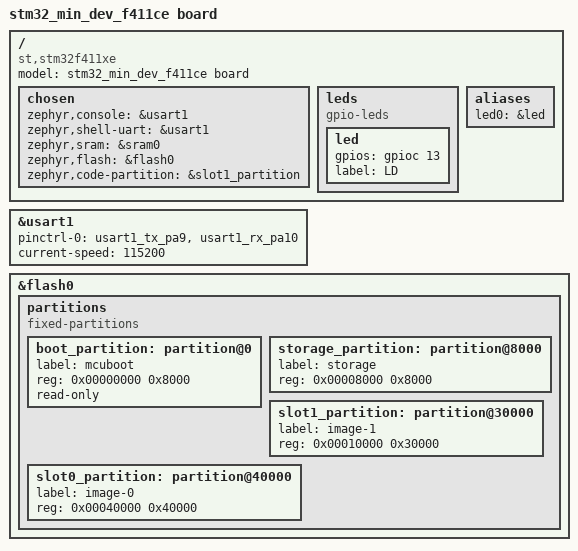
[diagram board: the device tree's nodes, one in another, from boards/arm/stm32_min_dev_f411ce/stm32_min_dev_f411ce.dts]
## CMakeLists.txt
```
# SPDX-License-Identifier: Apache-2.0

cmake_minimum_required(VERSION 3.13.1)

if( WIN32 ) # true if windows (32 and 64 bit)
set(GNUARMEMB_TOOLCHAIN_PATH "$ENV{GCC_ARM_HOME}")
endif()

set(ZEPHYR_TOOLCHAIN_VARIANT gnuarmemb)

list(APPEND BOARD_ROOT ${CMAKE_CURRENT_SOURCE_DIR})

message("----------------------------------------------------------------")
message("${BOARD_ROOT}")
message("${GNUARMEMB_TOOLCHAIN_PATH}")

find_package(Zephyr REQUIRED HINTS $ENV{ZEPHYR_BASE})


project(blinky)

target_sources(app PRIVATE src/main.c)
```

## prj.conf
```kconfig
CONFIG_GPIO=y
CONFIG_SIZE_OPTIMIZATIONS=y
```

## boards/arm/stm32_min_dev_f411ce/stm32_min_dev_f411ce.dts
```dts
/*
 * Copyright (c) 2017 Linaro Limited
 * Copyright (c) 2019 Centaur Analytics, Inc
 *
 * SPDX-License-Identifier: Apache-2.0
 */

/dts-v1/;
#include <st/f4/stm32f411Xe.dtsi>
#include <st/f4/stm32f411c(c-e)ux-pinctrl.dtsi>



/ {
	model = "stm32_min_dev_f411ce board";
	compatible = "st,stm32f411xe";

	chosen {
		zephyr,console = &usart1;
		zephyr,shell-uart = &usart1;
		zephyr,sram = &sram0;
		zephyr,flash = &flash0;
		zephyr,code-partition = &slot1_partition;
	};

	leds {
		compatible = "gpio-leds";
		led: led {
			gpios = <&gpioc 13 GPIO_ACTIVE_HIGH>;
			label = "LD";
		};
	};

	aliases {
		led0 = &led;
	};

};

&usart1 {
	pinctrl-0 = <&usart1_tx_pa9 &usart1_rx_pa10>;
	current-speed = <115200>;
	status = "okay";
};

&flash0 {
	/*
	 * For more information, see:
	 * https://docs.zephyrproject.org/latest/reference/devicetree/index.html#fixed-flash-partitions
	 */
	partitions {
		compatible = "fixed-partitions";
		#address-cells = <1>;
		#size-cells = <1>;

		/* KB for bootloader */
		boot_partition: partition@0 {
			label = "mcuboot";
			reg = <0x00000000 0x8000>;
			read-only;
		};

		/* storage: 32KB for settings */
		storage_partition: partition@8000 {
			label = "storage";
			reg = <0x00008000 0x8000>;
		};

		/* backup slot: 192KB */
		slot1_partition: partition@30000 {
			label = "image-1";
			reg = <0x00010000 0x30000>;
		};

		/* application image slot: 256KB */
		slot0_partition: partition@40000 {
			label = "image-0";
			reg = <0x00040000 0x40000>;
		};

	};
};
```

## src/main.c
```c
/*
 * Copyright (c) 2016 Intel Corporation
 *
 * SPDX-License-Identifier: Apache-2.0
 */

#include <zephyr.h>
#include <device.h>
#include <devicetree.h>
#include <drivers/gpio.h>

/* 1000 msec = 1 sec */
#define SLEEP_TIME_MS   1000

/* The devicetree node identifier for the "led0" alias. */
#define LED0_NODE DT_ALIAS(led0)

#if DT_NODE_HAS_STATUS(LED0_NODE, okay)
#define LED0	DT_GPIO_LABEL(LED0_NODE, gpios)
#define PIN	DT_GPIO_PIN(LED0_NODE, gpios)
#define FLAGS	DT_GPIO_FLAGS(LED0_NODE, gpios)
#else
/* A build error here means your board isn't set up to blink an LED. */
#error "Unsupported board: led0 devicetree alias is not defined"
#define LED0	""
#define PIN	0
#define FLAGS	0
#endif

void main(void)
{
	const struct device *dev;
	bool led_is_on = true;
	int ret;

	printk("Hello World! %s\n", CONFIG_BOARD);

	dev = device_get_binding(LED0);
	if (dev == NULL) {
		return;
	}

	ret = gpio_pin_configure(dev, PIN, GPIO_OUTPUT_ACTIVE | FLAGS);
	if (ret < 0) {
		return;
	}

	while (1) {
		gpio_pin_set(dev, PIN, (int)led_is_on);
		led_is_on = !led_is_on;
		k_msleep(SLEEP_TIME_MS);
	}
}
```
